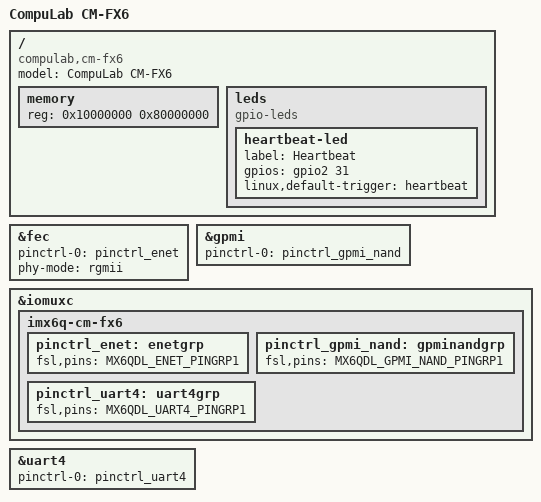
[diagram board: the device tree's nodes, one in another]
/*
 * Copyright 2013 CompuLab Ltd.
 *
 * Author: Valentin Raevsky <valentin@compulab.co.il>
 *
 * The code contained herein is licensed under the GNU General Public
 * License. You may obtain a copy of the GNU General Public License
 * Version 2 or later at the following locations:
 *
 * http://www.opensource.org/licenses/gpl-license.html
 * http://www.gnu.org/copyleft/gpl.html
 */

/dts-v1/;
#include "imx6q.dtsi"

/ {
	model = "CompuLab CM-FX6";
	compatible = "compulab,cm-fx6", "fsl,imx6q";

	memory {
		reg = <0x10000000 0x80000000>;
	};

	leds {
		compatible = "gpio-leds";

		heartbeat-led {
			label = "Heartbeat";
			gpios = <&gpio2 31 0>;
			linux,default-trigger = "heartbeat";
		};
	};
};

&fec {
	pinctrl-names = "default";
	pinctrl-0 = <&pinctrl_enet>;
	phy-mode = "rgmii";
	status = "okay";
};

&gpmi {
	pinctrl-names = "default";
	pinctrl-0 = <&pinctrl_gpmi_nand>;
	status = "okay";
};

&iomuxc {
	imx6q-cm-fx6 {
		pinctrl_enet: enetgrp {
			fsl,pins = <MX6QDL_ENET_PINGRP1>;
		};

		pinctrl_gpmi_nand: gpminandgrp {
			fsl,pins = <MX6QDL_GPMI_NAND_PINGRP1>;
		};

		pinctrl_uart4: uart4grp {
			fsl,pins = <MX6QDL_UART4_PINGRP1>;
		};
	};
};

&uart4 {
	pinctrl-names = "default";
	pinctrl-0 = <&pinctrl_uart4>;
	status = "okay";
};
